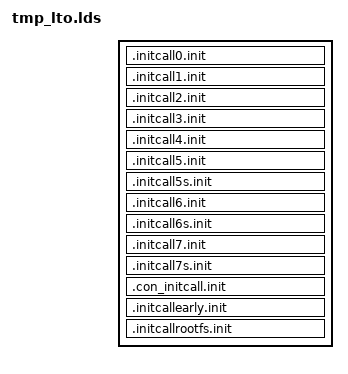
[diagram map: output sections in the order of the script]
SECTIONS {
	.initcall0.init : {
		*(.initcall0.init..ipc_ns_init) ;
		*(.initcall0.init..init_mmap_min_addr) ;
		*(.initcall0.init..pci_realloc_setup_params) ;
		*(.initcall0.init..net_ns_init) ;
	}
	.initcall1.init : {
		*(.initcall1.init..e820__register_nvs_regions) ;
		*(.initcall1.init..cpufreq_register_tsc_scaling) ;
		*(.initcall1.init..reboot_init) ;
		*(.initcall1.init..init_lapic_sysfs) ;
		*(.initcall1.init..alloc_frozen_cpus) ;
		*(.initcall1.init..cpu_hotplug_pm_sync_init) ;
		*(.initcall1.init..wq_sysfs_init) ;
		*(.initcall1.init..ksysfs_init) ;
		*(.initcall1.init..pm_init) ;
		*(.initcall1.init..pm_disk_init) ;
		*(.initcall1.init..swsusp_header_init) ;
		*(.initcall1.init..rcu_set_runtime_mode) ;
		*(.initcall1.init..init_jiffies_clocksource) ;
		*(.initcall1.init..futex_init) ;
		*(.initcall1.init..cgroup_wq_init) ;
		*(.initcall1.init..cgroup1_wq_init) ;
		*(.initcall1.init..init_zero_pfn) ;
		*(.initcall1.init..init_per_zone_wmark_min) ;
		*(.initcall1.init..fsnotify_init) ;
		*(.initcall1.init..filelock_init) ;
		*(.initcall1.init..init_misc_binfmt) ;
		*(.initcall1.init..init_script_binfmt) ;
		*(.initcall1.init..init_elf_binfmt) ;
		*(.initcall1.init..init_compat_elf_binfmt) ;
		*(.initcall1.init..debugfs_init) ;
		*(.initcall1.init..tracefs_init) ;
		*(.initcall1.init..prandom_init) ;
		*(.initcall1.init..iommu_init) ;
		*(.initcall1.init..component_debug_init) ;
		*(.initcall1.init..early_resume_init) ;
		*(.initcall1.init..cpufreq_core_init) ;
		*(.initcall1.init..cpuidle_init) ;
		*(.initcall1.init..capsule_reboot_register) ;
		*(.initcall1.init..bsp_pm_check_init) ;
		*(.initcall1.init..sock_init) ;
		*(.initcall1.init..net_inuse_init) ;
		*(.initcall1.init..net_defaults_init) ;
		*(.initcall1.init..init_default_flow_dissectors) ;
		*(.initcall1.init..netpoll_init) ;
		*(.initcall1.init..netlink_proto_init) ;
	}
	.initcall2.init : {
		*(.initcall2.init..irq_sysfs_init) ;
		*(.initcall2.init..audit_init) ;
		*(.initcall2.init..release_early_probes) ;
		*(.initcall2.init..bdi_class_init) ;
		*(.initcall2.init..mm_sysfs_init) ;
		*(.initcall2.init..pcibus_class_init) ;
		*(.initcall2.init..pci_driver_init) ;
		*(.initcall2.init..backlight_class_init) ;
		*(.initcall2.init..tty_class_init) ;
		*(.initcall2.init..vtconsole_class_init) ;
		*(.initcall2.init..iommu_dev_init) ;
		*(.initcall2.init..mipi_dsi_bus_init) ;
		*(.initcall2.init..software_node_init) ;
		*(.initcall2.init..wakeup_sources_debugfs_init) ;
		*(.initcall2.init..register_node_type) ;
		*(.initcall2.init..regmap_initcall) ;
		*(.initcall2.init..i2c_init) ;
		*(.initcall2.init..init_menu) ;
		*(.initcall2.init..pcc_init) ;
		*(.initcall2.init..amd_postcore_init) ;
		*(.initcall2.init..kobject_uevent_init) ;
	}
	.initcall3.init : {
		*(.initcall3.init..bts_init) ;
		*(.initcall3.init..pt_init) ;
		*(.initcall3.init..boot_params_ksysfs_init) ;
		*(.initcall3.init..sbf_init) ;
		*(.initcall3.init..arch_kdebugfs_init) ;
		*(.initcall3.init..intel_pconfig_init) ;
		*(.initcall3.init..mtrr_if_init) ;
		*(.initcall3.init..ffh_cstate_init) ;
		*(.initcall3.init..cryptomgr_init) ;
		*(.initcall3.init..acpi_pci_init) ;
		*(.initcall3.init..dma_channel_table_init) ;
		*(.initcall3.init..dma_bus_init) ;
		*(.initcall3.init..dmi_id_init) ;
		*(.initcall3.init..pci_arch_init) ;
	}
	.initcall4.init : {
		*(.initcall4.init..init_vdso) ;
		*(.initcall4.init..sysenter_setup) ;
		*(.initcall4.init..fixup_ht_bug) ;
		*(.initcall4.init..topology_init) ;
		*(.initcall4.init..intel_epb_init) ;
		*(.initcall4.init..mtrr_init_finialize) ;
		*(.initcall4.init..uid_cache_init) ;
		*(.initcall4.init..param_sysfs_init) ;
		*(.initcall4.init..user_namespace_sysctl_init) ;
		*(.initcall4.init..proc_schedstat_init) ;
		*(.initcall4.init..pm_sysrq_init) ;
		*(.initcall4.init..create_proc_profile) ;
		*(.initcall4.init..crash_save_vmcoreinfo_init) ;
		*(.initcall4.init..crash_notes_memory_init) ;
		*(.initcall4.init..cgroup_sysfs_init) ;
		*(.initcall4.init..cgroup_namespaces_init) ;
		*(.initcall4.init..init_kprobes) ;
		*(.initcall4.init..oom_init) ;
		*(.initcall4.init..default_bdi_init) ;
		*(.initcall4.init..percpu_enable_async) ;
		*(.initcall4.init..kcompactd_init) ;
		*(.initcall4.init..init_user_reserve) ;
		*(.initcall4.init..init_admin_reserve) ;
		*(.initcall4.init..init_reserve_notifier) ;
		*(.initcall4.init..swap_init_sysfs) ;
		*(.initcall4.init..swapfile_init) ;
		*(.initcall4.init..hugetlb_init) ;
		*(.initcall4.init..sel_ib_pkey_init) ;
		*(.initcall4.init..seqiv_module_init) ;
		*(.initcall4.init..echainiv_module_init) ;
		*(.initcall4.init..rsa_init) ;
		*(.initcall4.init..crypto_cmac_module_init) ;
		*(.initcall4.init..hmac_module_init) ;
		*(.initcall4.init..crypto_null_mod_init) ;
		*(.initcall4.init..md5_mod_init) ;
		*(.initcall4.init..sha1_generic_mod_init) ;
		*(.initcall4.init..sha256_generic_mod_init) ;
		*(.initcall4.init..crypto_cbc_module_init) ;
		*(.initcall4.init..crypto_ctr_module_init) ;
		*(.initcall4.init..crypto_gcm_module_init) ;
		*(.initcall4.init..crypto_ccm_module_init) ;
		*(.initcall4.init..des_generic_mod_init) ;
		*(.initcall4.init..aes_init) ;
		*(.initcall4.init..crc32c_mod_init) ;
		*(.initcall4.init..crypto_authenc_module_init) ;
		*(.initcall4.init..crypto_authenc_esn_module_init) ;
		*(.initcall4.init..drbg_init) ;
		*(.initcall4.init..ghash_mod_init) ;
		*(.initcall4.init..init_bio) ;
		*(.initcall4.init..blk_settings_init) ;
		*(.initcall4.init..blk_ioc_init) ;
		*(.initcall4.init..blk_softirq_init) ;
		*(.initcall4.init..blk_mq_init) ;
		*(.initcall4.init..genhd_device_init) ;
		*(.initcall4.init..pci_slot_init) ;
		*(.initcall4.init..fbmem_init) ;
		*(.initcall4.init..acpi_init) ;
		*(.initcall4.init..pnp_init) ;
		*(.initcall4.init..misc_init) ;
		*(.initcall4.init..vga_arb_device_init) ;
		*(.initcall4.init..cn_init) ;
		*(.initcall4.init..dma_buf_init) ;
		*(.initcall4.init..init_scsi) ;
		*(.initcall4.init..ata_init) ;
		*(.initcall4.init..phy_init) ;
		*(.initcall4.init..init_pcmcia_cs) ;
		*(.initcall4.init..usb_common_init) ;
		*(.initcall4.init..usb_init) ;
		*(.initcall4.init..serio_init) ;
		*(.initcall4.init..input_init) ;
		*(.initcall4.init..rtc_init) ;
		*(.initcall4.init..pps_init) ;
		*(.initcall4.init..ptp_init) ;
		*(.initcall4.init..power_supply_class_init) ;
		*(.initcall4.init..hwmon_init) ;
		*(.initcall4.init..md_init) ;
		*(.initcall4.init..edac_init) ;
		*(.initcall4.init..leds_init) ;
		*(.initcall4.init..dmi_init) ;
		*(.initcall4.init..efisubsys_init) ;
		*(.initcall4.init..ras_init) ;
		*(.initcall4.init..nvmem_init) ;
		*(.initcall4.init..init_soundcore) ;
		*(.initcall4.init..alsa_sound_init) ;
		*(.initcall4.init..alsa_seq_device_init) ;
		*(.initcall4.init..hda_bus_init) ;
		*(.initcall4.init..pci_subsys_init) ;
		*(.initcall4.init..proto_init) ;
		*(.initcall4.init..net_dev_init) ;
		*(.initcall4.init..neigh_init) ;
		*(.initcall4.init..fib_notifier_init) ;
		*(.initcall4.init..fib_rules_init) ;
		*(.initcall4.init..pktsched_init) ;
		*(.initcall4.init..tc_filter_init) ;
		*(.initcall4.init..tc_action_init) ;
		*(.initcall4.init..genl_init) ;
		*(.initcall4.init..nexthop_init) ;
		*(.initcall4.init..cipso_v4_init) ;
		*(.initcall4.init..ieee80211_init) ;
		*(.initcall4.init..netlbl_init) ;
		*(.initcall4.init..rfkill_init) ;
	}
	.initcall5.init : {
		*(.initcall5.init..nmi_warning_debugfs) ;
		*(.initcall5.init..save_microcode_in_initrd) ;
		*(.initcall5.init..hpet_late_init) ;
		*(.initcall5.init..init_amd_nbs) ;
		*(.initcall5.init..clocksource_done_booting) ;
		*(.initcall5.init..tracer_init_tracefs) ;
		*(.initcall5.init..init_trace_printk_function_export) ;
		*(.initcall5.init..init_kprobe_trace) ;
		*(.initcall5.init..init_dynamic_event) ;
		*(.initcall5.init..init_uprobe_trace) ;
		*(.initcall5.init..init_pipe_fs) ;
		*(.initcall5.init..inotify_user_setup) ;
		*(.initcall5.init..eventpoll_init) ;
		*(.initcall5.init..anon_inode_init) ;
		*(.initcall5.init..proc_locks_init) ;
		*(.initcall5.init..dquot_init) ;
		*(.initcall5.init..quota_init) ;
		*(.initcall5.init..proc_cmdline_init) ;
		*(.initcall5.init..proc_consoles_init) ;
		*(.initcall5.init..proc_cpuinfo_init) ;
		*(.initcall5.init..proc_devices_init) ;
		*(.initcall5.init..proc_interrupts_init) ;
		*(.initcall5.init..proc_loadavg_init) ;
		*(.initcall5.init..proc_meminfo_init) ;
		*(.initcall5.init..proc_stat_init) ;
		*(.initcall5.init..proc_uptime_init) ;
		*(.initcall5.init..proc_version_init) ;
		*(.initcall5.init..proc_softirqs_init) ;
		*(.initcall5.init..proc_kcore_init) ;
		*(.initcall5.init..vmcore_init) ;
		*(.initcall5.init..proc_kmsg_init) ;
		*(.initcall5.init..proc_page_init) ;
		*(.initcall5.init..init_ramfs_fs) ;
		*(.initcall5.init..init_hugetlbfs_fs) ;
		*(.initcall5.init..blk_scsi_ioctl_init) ;
		*(.initcall5.init..acpi_event_init) ;
		*(.initcall5.init..pnp_system_init) ;
		*(.initcall5.init..pnpacpi_init) ;
		*(.initcall5.init..chr_dev_init) ;
		*(.initcall5.init..firmware_class_init) ;
		*(.initcall5.init..init_pcmcia_bus) ;
		*(.initcall5.init..thermal_init) ;
		*(.initcall5.init..cpufreq_gov_performance_init) ;
		*(.initcall5.init..cpufreq_gov_userspace_init) ;
		*(.initcall5.init..init_acpi_pm_clocksource) ;
		*(.initcall5.init..pcibios_assign_resources) ;
		*(.initcall5.init..sysctl_core_init) ;
		*(.initcall5.init..eth_offload_init) ;
		*(.initcall5.init..ipv4_offload_init) ;
		*(.initcall5.init..inet_init) ;
		*(.initcall5.init..af_unix_init) ;
		*(.initcall5.init..ipv6_offload_init) ;
		*(.initcall5.init..init_sunrpc) ;
		*(.initcall5.init..cfg80211_init) ;
	}
	.initcall5s.init : {
		*(.initcall5s.init..pci_apply_final_quirks) ;
		*(.initcall5s.init..acpi_reserve_resources) ;
	}
	.initcall6.init : {
		*(.initcall6.init..ia32_binfmt_init) ;
		*(.initcall6.init..amd_uncore_init) ;
		*(.initcall6.init..amd_ibs_init) ;
		*(.initcall6.init..amd_iommu_pc_init) ;
		*(.initcall6.init..msr_init) ;
		*(.initcall6.init..rapl_pmu_init) ;
		*(.initcall6.init..intel_uncore_init) ;
		*(.initcall6.init..cstate_pmu_init) ;
		*(.initcall6.init..register_kernel_offset_dumper) ;
		*(.initcall6.init..i8259A_init_ops) ;
		*(.initcall6.init..init_tsc_clocksource) ;
		*(.initcall6.init..add_rtc_cmos) ;
		*(.initcall6.init..i8237A_init_ops) ;
		*(.initcall6.init..umwait_init) ;
		*(.initcall6.init..thermal_throttle_init_device) ;
		*(.initcall6.init..msr_init) ;
		*(.initcall6.init..cpuid_init) ;
		*(.initcall6.init..ioapic_init_ops) ;
		*(.initcall6.init..add_pcspkr) ;
		*(.initcall6.init..start_periodic_check_for_corruption) ;
		*(.initcall6.init..sysfb_init) ;
		*(.initcall6.init..audit_classes_init) ;
		*(.initcall6.init..iosf_mbi_init) ;
		*(.initcall6.init..proc_execdomains_init) ;
		*(.initcall6.init..register_warn_debugfs) ;
		*(.initcall6.init..cpuhp_sysfs_init) ;
		*(.initcall6.init..ioresources_init) ;
		*(.initcall6.init..snapshot_device_init) ;
		*(.initcall6.init..irq_pm_init_ops) ;
		*(.initcall6.init..timekeeping_init_ops) ;
		*(.initcall6.init..init_clocksource_sysfs) ;
		*(.initcall6.init..init_timer_list_procfs) ;
		*(.initcall6.init..alarmtimer_init) ;
		*(.initcall6.init..init_posix_timers) ;
		*(.initcall6.init..clockevents_init_sysfs) ;
		*(.initcall6.init..proc_dma_init) ;
		*(.initcall6.init..modules_wq_init) ;
		*(.initcall6.init..proc_modules_init) ;
		*(.initcall6.init..kallsyms_init) ;
		*(.initcall6.init..pid_namespaces_init) ;
		*(.initcall6.init..audit_watch_init) ;
		*(.initcall6.init..audit_fsnotify_init) ;
		*(.initcall6.init..audit_tree_init) ;
		*(.initcall6.init..seccomp_sysctl_init) ;
		*(.initcall6.init..utsname_sysctl_init) ;
		*(.initcall6.init..init_tracepoints) ;
		*(.initcall6.init..init_blk_tracer) ;
		*(.initcall6.init..perf_event_sysfs_init) ;
		*(.initcall6.init..system_trusted_keyring_init) ;
		*(.initcall6.init..kswapd_init) ;
		*(.initcall6.init..extfrag_debug_init) ;
		*(.initcall6.init..mm_compute_batch_init) ;
		*(.initcall6.init..slab_proc_init) ;
		*(.initcall6.init..workingset_init) ;
		*(.initcall6.init..proc_vmalloc_init) ;
		*(.initcall6.init..procswaps_init) ;
		*(.initcall6.init..slab_sysfs_init) ;
		*(.initcall6.init..fcntl_init) ;
		*(.initcall6.init..proc_filesystems_init) ;
		*(.initcall6.init..start_dirtytime_writeback) ;
		*(.initcall6.init..blkdev_init) ;
		*(.initcall6.init..dio_init) ;
		*(.initcall6.init..dnotify_init) ;
		*(.initcall6.init..aio_setup) ;
		*(.initcall6.init..io_uring_init) ;
		*(.initcall6.init..init_sys32_ioctl) ;
		*(.initcall6.init..mbcache_init) ;
		*(.initcall6.init..init_grace) ;
		*(.initcall6.init..init_v2_quota_format) ;
		*(.initcall6.init..init_devpts_fs) ;
		*(.initcall6.init..ext4_init_fs) ;
		*(.initcall6.init..journal_init) ;
		*(.initcall6.init..init_fat_fs) ;
		*(.initcall6.init..init_vfat_fs) ;
		*(.initcall6.init..init_msdos_fs) ;
		*(.initcall6.init..init_iso9660_fs) ;
		*(.initcall6.init..init_nfs_fs) ;
		*(.initcall6.init..init_nfs_v2) ;
		*(.initcall6.init..init_nfs_v3) ;
		*(.initcall6.init..init_nfs_v4) ;
		*(.initcall6.init..init_nlm) ;
		*(.initcall6.init..init_nls_cp437) ;
		*(.initcall6.init..init_nls_ascii) ;
		*(.initcall6.init..init_nls_iso8859_1) ;
		*(.initcall6.init..init_nls_utf8) ;
		*(.initcall6.init..init_autofs_fs) ;
		*(.initcall6.init..ipc_init) ;
		*(.initcall6.init..ipc_sysctl_init) ;
		*(.initcall6.init..init_mqueue_fs) ;
		*(.initcall6.init..key_proc_init) ;
		*(.initcall6.init..selinux_nf_ip_init) ;
		*(.initcall6.init..init_sel_fs) ;
		*(.initcall6.init..selnl_init) ;
		*(.initcall6.init..sel_netif_init) ;
		*(.initcall6.init..sel_netnode_init) ;
		*(.initcall6.init..sel_netport_init) ;
		*(.initcall6.init..aurule_init) ;
		*(.initcall6.init..crypto_algapi_init) ;
		*(.initcall6.init..jent_mod_init) ;
		*(.initcall6.init..asymmetric_key_init) ;
		*(.initcall6.init..x509_key_init) ;
		*(.initcall6.init..proc_genhd_init) ;
		*(.initcall6.init..bsg_init) ;
		*(.initcall6.init..deadline_init) ;
		*(.initcall6.init..kyber_init) ;
		*(.initcall6.init..percpu_counter_startup) ;
		*(.initcall6.init..sg_pool_init) ;
		*(.initcall6.init..pci_proc_init) ;
		*(.initcall6.init..pcie_portdrv_init) ;
		*(.initcall6.init..pci_hotplug_init) ;
		*(.initcall6.init..genericbl_driver_init) ;
		*(.initcall6.init..efifb_driver_init) ;
		*(.initcall6.init..acpi_ac_init) ;
		*(.initcall6.init..acpi_button_driver_init) ;
		*(.initcall6.init..acpi_fan_driver_init) ;
		*(.initcall6.init..acpi_video_init) ;
		*(.initcall6.init..acpi_processor_driver_init) ;
		*(.initcall6.init..acpi_thermal_init) ;
		*(.initcall6.init..acpi_battery_init) ;
		*(.initcall6.init..bgrt_init) ;
		*(.initcall6.init..gpio_clk_driver_init) ;
		*(.initcall6.init..plt_clk_driver_init) ;
		*(.initcall6.init..n_null_init) ;
		*(.initcall6.init..pty_init) ;
		*(.initcall6.init..sysrq_init) ;
		*(.initcall6.init..serial8250_init) ;
		*(.initcall6.init..serial_pci_driver_init) ;
		*(.initcall6.init..exar_pci_driver_init) ;
		*(.initcall6.init..lpss8250_pci_driver_init) ;
		*(.initcall6.init..mid8250_pci_driver_init) ;
		*(.initcall6.init..hpet_init) ;
		*(.initcall6.init..nvram_module_init) ;
		*(.initcall6.init..hwrng_modinit) ;
		*(.initcall6.init..mod_init) ;
		*(.initcall6.init..agp_init) ;
		*(.initcall6.init..agp_amd64_mod_init) ;
		*(.initcall6.init..agp_intel_init) ;
		*(.initcall6.init..drm_kms_helper_init) ;
		*(.initcall6.init..drm_core_init) ;
		*(.initcall6.init..i915_init) ;
		*(.initcall6.init..cn_proc_init) ;
		*(.initcall6.init..topology_sysfs_init) ;
		*(.initcall6.init..cacheinfo_sysfs_init) ;
		*(.initcall6.init..loop_init) ;
		*(.initcall6.init..mac_hid_init) ;
		*(.initcall6.init..spi_transport_init) ;
		*(.initcall6.init..init_sd) ;
		*(.initcall6.init..init_sr) ;
		*(.initcall6.init..init_sg) ;
		*(.initcall6.init..ahci_pci_driver_init) ;
		*(.initcall6.init..piix_init) ;
		*(.initcall6.init..amd_pci_driver_init) ;
		*(.initcall6.init..oldpiix_pci_driver_init) ;
		*(.initcall6.init..sch_pci_driver_init) ;
		*(.initcall6.init..net_olddevs_init) ;
		*(.initcall6.init..blackhole_netdev_init) ;
		*(.initcall6.init..phy_module_init) ;
		*(.initcall6.init..tg3_driver_init) ;
		*(.initcall6.init..e100_init_module) ;
		*(.initcall6.init..e1000_init_module) ;
		*(.initcall6.init..e1000_init_module) ;
		*(.initcall6.init..sky2_init_module) ;
		*(.initcall6.init..forcedeth_pci_driver_init) ;
		*(.initcall6.init..rtl8139_init_module) ;
		*(.initcall6.init..rtl8169_pci_driver_init) ;
		*(.initcall6.init..cdrom_init) ;
		*(.initcall6.init..nonstatic_sysfs_init) ;
		*(.initcall6.init..yenta_cardbus_driver_init) ;
		*(.initcall6.init..mon_init) ;
		*(.initcall6.init..ehci_hcd_init) ;
		*(.initcall6.init..ehci_pci_init) ;
		*(.initcall6.init..ohci_hcd_mod_init) ;
		*(.initcall6.init..ohci_pci_init) ;
		*(.initcall6.init..uhci_hcd_init) ;
		*(.initcall6.init..xhci_hcd_init) ;
		*(.initcall6.init..xhci_pci_init) ;
		*(.initcall6.init..usblp_driver_init) ;
		*(.initcall6.init..usb_storage_driver_init) ;
		*(.initcall6.init..i8042_init) ;
		*(.initcall6.init..serport_init) ;
		*(.initcall6.init..input_leds_init) ;
		*(.initcall6.init..evdev_init) ;
		*(.initcall6.init..atkbd_init) ;
		*(.initcall6.init..psmouse_init) ;
		*(.initcall6.init..cmos_init) ;
		*(.initcall6.init..smbalert_driver_init) ;
		*(.initcall6.init..i2c_i801_init) ;
		*(.initcall6.init..dm_init) ;
		*(.initcall6.init..dm_mirror_init) ;
		*(.initcall6.init..dm_dirty_log_init) ;
		*(.initcall6.init..dm_zero_init) ;
		*(.initcall6.init..cpufreq_gov_dbs_init) ;
		*(.initcall6.init..intel_pstate_init) ;
		*(.initcall6.init..efivars_sysfs_init) ;
		*(.initcall6.init..esrt_sysfs_init) ;
		*(.initcall6.init..hid_init) ;
		*(.initcall6.init..hid_generic_init) ;
		*(.initcall6.init..a4_driver_init) ;
		*(.initcall6.init..apple_driver_init) ;
		*(.initcall6.init..belkin_driver_init) ;
		*(.initcall6.init..ch_driver_init) ;
		*(.initcall6.init..ch_driver_init) ;
		*(.initcall6.init..cp_driver_init) ;
		*(.initcall6.init..ez_driver_init) ;
		*(.initcall6.init..gyration_driver_init) ;
		*(.initcall6.init..ite_driver_init) ;
		*(.initcall6.init..ks_driver_init) ;
		*(.initcall6.init..lg_driver_init) ;
		*(.initcall6.init..ms_driver_init) ;
		*(.initcall6.init..mr_driver_init) ;
		*(.initcall6.init..ntrig_driver_init) ;
		*(.initcall6.init..pl_driver_init) ;
		*(.initcall6.init..pl_driver_init) ;
		*(.initcall6.init..redragon_driver_init) ;
		*(.initcall6.init..samsung_driver_init) ;
		*(.initcall6.init..sony_init) ;
		*(.initcall6.init..sp_driver_init) ;
		*(.initcall6.init..ts_driver_init) ;
		*(.initcall6.init..hid_init) ;
		*(.initcall6.init..eeepc_laptop_init) ;
		*(.initcall6.init..pmc_atom_init) ;
		*(.initcall6.init..alsa_hwdep_init) ;
		*(.initcall6.init..alsa_timer_init) ;
		*(.initcall6.init..snd_hrtimer_init) ;
		*(.initcall6.init..alsa_pcm_init) ;
		*(.initcall6.init..alsa_seq_init) ;
		*(.initcall6.init..alsa_seq_dummy_init) ;
		*(.initcall6.init..azx_driver_init) ;
		*(.initcall6.init..pm_check_save_msr) ;
		*(.initcall6.init..sock_diag_init) ;
		*(.initcall6.init..blackhole_init) ;
		*(.initcall6.init..nfnetlink_init) ;
		*(.initcall6.init..nfnetlink_log_init) ;
		*(.initcall6.init..nf_conntrack_standalone_init) ;
		*(.initcall6.init..ctnetlink_init) ;
		*(.initcall6.init..nf_conntrack_ftp_init) ;
		*(.initcall6.init..nf_conntrack_irc_init) ;
		*(.initcall6.init..nf_conntrack_sip_init) ;
		*(.initcall6.init..nf_nat_init) ;
		*(.initcall6.init..nf_nat_ftp_init) ;
		*(.initcall6.init..nf_nat_irc_init) ;
		*(.initcall6.init..nf_nat_sip_init) ;
		*(.initcall6.init..xt_init) ;
		*(.initcall6.init..tcpudp_mt_init) ;
		*(.initcall6.init..connsecmark_tg_init) ;
		*(.initcall6.init..nflog_tg_init) ;
		*(.initcall6.init..secmark_tg_init) ;
		*(.initcall6.init..tcpmss_tg_init) ;
		*(.initcall6.init..conntrack_mt_init) ;
		*(.initcall6.init..policy_mt_init) ;
		*(.initcall6.init..state_mt_init) ;
		*(.initcall6.init..gre_offload_init) ;
		*(.initcall6.init..sysctl_ipv4_init) ;
		*(.initcall6.init..tunnel4_init) ;
		*(.initcall6.init..nf_defrag_init) ;
		*(.initcall6.init..ip_tables_init) ;
		*(.initcall6.init..iptable_filter_init) ;
		*(.initcall6.init..iptable_mangle_init) ;
		*(.initcall6.init..reject_tg_init) ;
		*(.initcall6.init..cubictcp_register) ;
		*(.initcall6.init..xfrm_user_init) ;
		*(.initcall6.init..inet6_init) ;
		*(.initcall6.init..ah6_init) ;
		*(.initcall6.init..esp6_init) ;
		*(.initcall6.init..ip6_tables_init) ;
		*(.initcall6.init..ip6table_filter_init) ;
		*(.initcall6.init..ip6table_mangle_init) ;
		*(.initcall6.init..nf_defrag_init) ;
		*(.initcall6.init..ipv6header_mt6_init) ;
		*(.initcall6.init..reject_tg6_init) ;
		*(.initcall6.init..sit_init) ;
		*(.initcall6.init..packet_init) ;
		*(.initcall6.init..init_rpcsec_gss) ;
		*(.initcall6.init..init_dns_resolver) ;
	}
	.initcall6s.init : {
		*(.initcall6s.init..mcheck_init_device) ;
	}
	.initcall7.init : {
		*(.initcall7.init..mcheck_late_init) ;
		*(.initcall7.init..severities_debugfs_init) ;
		*(.initcall7.init..threshold_init_device) ;
		*(.initcall7.init..microcode_init) ;
		*(.initcall7.init..hpet_insert_resource) ;
		*(.initcall7.init..update_mp_table) ;
		*(.initcall7.init..lapic_insert_resource) ;
		*(.initcall7.init..print_ICs) ;
		*(.initcall7.init..pat_memtype_list_init) ;
		*(.initcall7.init..create_tlb_single_page_flush_ceiling) ;
		*(.initcall7.init..create_init_pkru_value) ;
		*(.initcall7.init..init_oops_id) ;
		*(.initcall7.init..sched_clock_init_late) ;
		*(.initcall7.init..pm_qos_power_init) ;
		*(.initcall7.init..pm_debugfs_init) ;
		*(.initcall7.init..printk_late_init) ;
		*(.initcall7.init..init_srcu_module_notifier) ;
		*(.initcall7.init..swiotlb_create_debugfs) ;
		*(.initcall7.init..tk_debug_sleep_time_init) ;
		*(.initcall7.init..debugfs_kprobe_init) ;
		*(.initcall7.init..taskstats_init) ;
		*(.initcall7.init..load_system_certificate_list) ;
		*(.initcall7.init..fault_around_debugfs) ;
		*(.initcall7.init..max_swapfiles_check) ;
		*(.initcall7.init..check_early_ioremap_leak) ;
		*(.initcall7.init..init_root_keyring) ;
		*(.initcall7.init..integrity_fs_init) ;
		*(.initcall7.init..prandom_reseed) ;
		*(.initcall7.init..init_error_injection) ;
		*(.initcall7.init..pci_resource_alignment_sysfs_init) ;
		*(.initcall7.init..pci_sysfs_init) ;
		*(.initcall7.init..clk_debug_init) ;
		*(.initcall7.init..dmar_free_unused_resources) ;
		*(.initcall7.init..deferred_probe_initcall) ;
		*(.initcall7.init..late_resume_init) ;
		*(.initcall7.init..init_netconsole) ;
		*(.initcall7.init..acpi_cpufreq_init) ;
		*(.initcall7.init..firmware_memmap_init) ;
		*(.initcall7.init..register_update_efi_random_seed) ;
		*(.initcall7.init..efi_shutdown_init) ;
		*(.initcall7.init..pci_mmcfg_late_insert_resources) ;
		*(.initcall7.init..tcp_congestion_default) ;
		*(.initcall7.init..ip_auto_config) ;
		*(.initcall7.init..regulatory_init_db) ;
	}
	.initcall7s.init : {
		*(.initcall7s.init..software_resume) ;
		*(.initcall7s.init..clear_boot_tracer) ;
		*(.initcall7s.init..tracing_set_default_clock) ;
		*(.initcall7s.init..fb_logo_late_init) ;
		*(.initcall7s.init..clk_disable_unused) ;
		*(.initcall7s.init..alsa_sound_last_init) ;
	}
	.con_initcall.init : {
		*(.con_initcall.init..con_init) ;
		*(.con_initcall.init..univ8250_console_init) ;
	}
	.initcallearly.init : {
		*(.initcallearly.init..trace_init_flags_sys_enter) ;
		*(.initcallearly.init..trace_init_flags_sys_exit) ;
		*(.initcallearly.init..init_hw_perf_events) ;
		*(.initcallearly.init..init_real_mode) ;
		*(.initcallearly.init..trace_init_perf_perm_irq_work_exit) ;
		*(.initcallearly.init..validate_x2apic) ;
		*(.initcallearly.init..register_nmi_cpu_backtrace_handler) ;
		*(.initcallearly.init..spawn_ksoftirqd) ;
		*(.initcallearly.init..migration_init) ;
		*(.initcallearly.init..srcu_bootup_announce) ;
		*(.initcallearly.init..rcu_spawn_core_kthreads) ;
		*(.initcallearly.init..rcu_spawn_gp_kthread) ;
		*(.initcallearly.init..check_cpu_stall_init) ;
		*(.initcallearly.init..rcu_sysrq_init) ;
		*(.initcallearly.init..cpu_stop_init) ;
		*(.initcallearly.init..init_events) ;
		*(.initcallearly.init..init_trace_printk) ;
		*(.initcallearly.init..event_trace_enable_again) ;
		*(.initcallearly.init..mce_amd_init) ;
		*(.initcallearly.init..efi_memreserve_root_init) ;
		*(.initcallearly.init..initialize_ptr_random) ;
	}
	.initcallrootfs.init : {
		*(.initcallrootfs.init..populate_rootfs) ;
		*(.initcallrootfs.init..pci_iommu_init) ;
		*(.initcallrootfs.init..calgary_fixup_tce_spaces) ;
	}
}
